# CEC1702 register map
Vendor: Microchip Technology; Series: CEC1702Q; File version: 0
CPU: CM4 r1p0, little endian, MPU, FPU, 3 interrupt priority bits, 155 interrupts
Registers are 32-bit, read-write, reset 0x0 unless marked. A register's access mark holds for its fields unless they carry their own. Offsets are from the block's base; [hi:lo] are bit positions.

## VBAT — The VBAT Register Bank block is a block implemented for aggregating miscellaneous battery-backed registers required the host and by the Embedded Controller (EC) Subsystem that are not unique to a block implemented in the EC subsystem.
Base 0x4000A400; register names take the prefix VBAT_
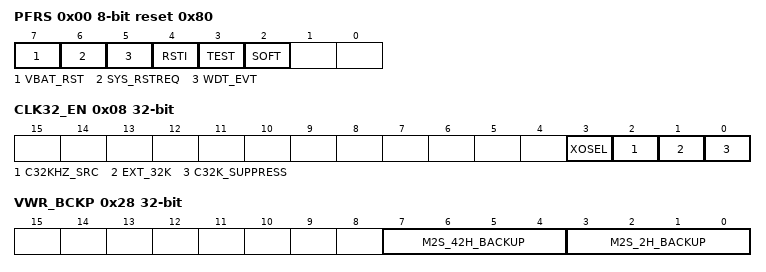
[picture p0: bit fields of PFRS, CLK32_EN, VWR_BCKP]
0x00 PFRS 8-bit reset 0x80 — The Power-Fail and Reset Status Register collects and retains the VBAT RST and WDT event status when VCC1 is unpowered.
  [7] VBAT_RST — The VBAT RST bit is set to '1' by hardware when a RESET_VBAT is detected. This is the register default value. To clear VBAT RST EC firmware must write a '1' to this bit; writing a '0' to VBAT RST has no affect.(R/WC)
  [6] SYS_RSTREQ — This bit is set to '1b' if a RESET_SYS was triggered by an ARM SYS_RSTREQ event. This bit is cleared to '0b' when written with a '1b'; writes of a '0b' have no effect. (R/WC)
  [5] WDT_EVT — This bit is set to '1b' if a RESET_SYS was triggered by a Watchdog Timer event. This bit is cleared to '0b' when written with a '1b'; writes of a '0b' have no effect. (R/WC)
  [4] RSTI — This bit is set to '1b' if a RESET_SYS was triggered by a low signal on the RSTI# input pin. This bit is cleared to '0b' when written with a '1b'; writes of a '0b' have no effect. (R/WC)
  [3] TEST
  [2] SOFT — This bit is set to '1b' if a was triggered by an assertion of the SOFT_SYS_RESET bit in the System Reset Register. This bit is cleared to '0b' when written with a '1b'; writes of a '0b' have no effect. (R/WC)
0x08 CLK32_EN — CLOCK ENABLE
  [3] XOSEL — This bit selects between a single-ended clock source for the crystal oscillator or an external parallel crystal. 1= the Crystal Oscillator is driven by a single-ended 32KHz clock source connected to the XTAL2 pin. 0= the Crystal Oscillator requires a 32KHz parallel resonant crystal connected between the XTAL1 and XTAL2 pins (default).
  [2] C32KHZ_SRC — This field determines the source for the always-on 32KHz internal clock source. If set to '1b', this bit will only take effect if an active clock has been detected on the crystal pins. Once the 32KHz source has been switched, activity detection on the crystal no longer functions. Therefore, if the crystal oscillator uses a single-ended input, once started that input must not stop while this bit is '1b'. 1=Crystal Oscillator. The selection between a singled-ended input or a resonant crystal is determined by XOSEL in this register. 0=Silicon Oscillator.
  [1] EXT_32K — This bit selects the source for the 32KHz clock domain. 1=The 32KHZ_IN VTR-powered pin is used as a source for the 32KHz clock domain. If an activity detector does not detect a clock on the selected source, the always-on 32KHz internal clock source is automatically selected. 0=The always-on32Khz clock source is used as the source for the 32KHz clock domain.
  [0] C32K_SUPPRESS — 1=32KHz clock domain is off while VTR is off (i.e., while on VBAT only). The 32KHz domain is always on while VTR is on, so the PLL always has a reference. 0=32KHz clock domain is enabled while VTR is off (i.e., while on VBAT only). The clock source for the 32KHz domain is determined by the other bits in this register
0x20 MCNT_LO — MONOTONIC COUNTER
  [31:0] MON_CNT — Read-only register that increments by 1 every time it is read. It is reset to 0 on a VBAT Power On Reset.
0x24 MCNT_HI — COUNTER HIWORD
  [31:0] CNT_HWRD — Thirty-two bit read/write register. If software sets this register to an incrementing value, based on an external non-volatile store, this register may be combined with the Monotonic Counter Register to form a 64-bit monotonic counter.
0x28 VWR_BCKP
  [7:4] M2S_42H_BACKUP — The Boot ROM firmware will copy this field into the SRC3 to SRC0 bits of the Master-to-Slave Virtual Wire Register that corresponds to Virtual Wire Index 42h on a RESET_SYS. If software always saves the state of the Index 2h SRC bits on the falling edge of the SUSWARN# virtual wire, the state of the four SRC bits will be synchronized to the state of the four bits in the core logic.
  [3:0] M2S_2H_BACKUP — The Boot ROM firmware will copy this field into the SRC3 to SRC0 bits of the Master-to-Slave Virtual Wire Register that corresponds to Virtual Wire Index 2h on a RESET_SYS. If software always saves the state of the Index 2h SRC bits on the falling edge of the SUSWARN# virtual wire, the state of the four SRC bits will be synchronized to the state of the four bits in the core logic.
